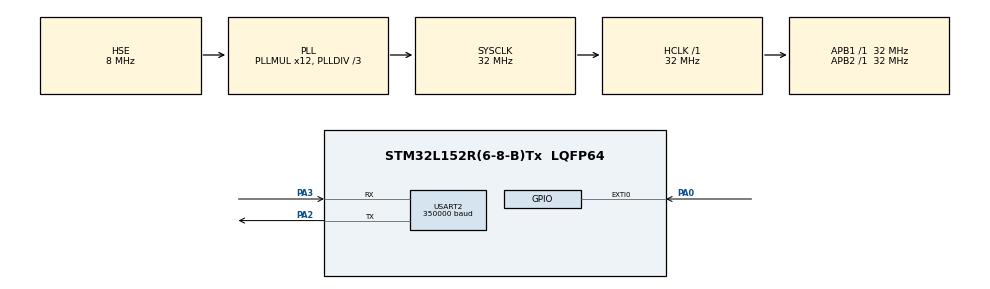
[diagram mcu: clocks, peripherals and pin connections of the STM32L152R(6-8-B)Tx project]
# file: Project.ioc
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ADC.Channel-0\#ChannelRegularConversion=ADC_CHANNEL_VREFINT
ADC.Channel-2\#ChannelRegularConversion=ADC_CHANNEL_TEMPSENSOR
ADC.ContinuousConvMode=ENABLE
ADC.DMAContinuousRequests=ENABLE
ADC.DataAlign=ADC_DATAALIGN_RIGHT
ADC.EOCSelection=ADC_EOC_SINGLE_CONV
ADC.EnableAnalogWatchDog=false
ADC.NbrOfConversion=2
ADC.NbrOfConversionFlag=1
ADC.Rank-0\#ChannelRegularConversion=1
ADC.Rank-2\#ChannelRegularConversion=2
ADC.Resolution=ADC_RESOLUTION_12B
ADC.SamplingTime-0\#ChannelRegularConversion=ADC_SAMPLETIME_192CYCLES
ADC.SamplingTime-2\#ChannelRegularConversion=ADC_SAMPLETIME_192CYCLES
ADC.ScanConvMode=ADC_SCAN_ENABLE
Dma.ADC.0.Direction=DMA_PERIPH_TO_MEMORY
Dma.ADC.0.Instance=DMA1_Channel1
Dma.ADC.0.MemDataAlignment=DMA_MDATAALIGN_WORD
Dma.ADC.0.MemInc=DMA_MINC_ENABLE
Dma.ADC.0.Mode=DMA_CIRCULAR
Dma.ADC.0.PeriphDataAlignment=DMA_PDATAALIGN_WORD
Dma.ADC.0.PeriphInc=DMA_PINC_DISABLE
Dma.ADC.0.Priority=DMA_PRIORITY_HIGH
Dma.Request0=ADC
Mcu.Family=STM32L1
Mcu.Name=STM32L152R(6-8-B)Tx
Mcu.Package=LQFP64
NVIC.ADC1_IRQn=true\:0\:0\:false\:false\:true\:true\:true
NVIC.DMA1_Channel1_IRQn=true\:0\:0\:false\:false\:true\:false\:true
NVIC.EXTI0_IRQn=true\:0\:0\:false\:false\:true\:true\:true
NVIC.PriorityGroup=NVIC_PRIORITYGROUP_4
PA0-WKUP1.Signal=GPXTI0
PA2.Mode=Asynchronous
PA2.Signal=USART2_TX
PA3.Mode=Asynchronous
PA3.Signal=USART2_RX
PC14-OSC32_IN.Mode=LSE-External-Oscillator
PC14-OSC32_IN.Signal=RCC_OSC32_IN
PC15-OSC32_OUT.Mode=LSE-External-Oscillator
PC15-OSC32_OUT.Signal=RCC_OSC32_OUT
PH0-OSC_IN.Mode=HSE-External-Oscillator
PH0-OSC_IN.Signal=RCC_OSC_IN
PH1-OSC_OUT.Mode=HSE-External-Oscillator
PH1-OSC_OUT.Signal=RCC_OSC_OUT
ProjectManager.HeapSize=0x200
ProjectManager.StackSize=0x400
ProjectManager.TargetToolchain=STM32CubeIDE
RCC.48MHZClocksFreq_Value=48000000
RCC.AHBFreq_Value=32000000
RCC.APB1Freq_Value=32000000
RCC.APB1TimFreq_Value=32000000
RCC.APB2Freq_Value=32000000
RCC.APB2TimFreq_Value=32000000
RCC.HCLKFreq_Value=32000000
RCC.HSE_VALUE=8000000
RCC.HSI_VALUE=16000000
RCC.MSI_VALUE=2097000
RCC.PLLDIV=RCC_PLL_DIV3
RCC.PLLMUL=RCC_PLL_MUL12
RCC.PLLSourceVirtual=RCC_PLLSOURCE_HSE
RCC.RTCClockSelectionVirtual=RCC_RTCCLKSOURCE_LSE
RCC.SYSCLKFreq_VALUE=32000000
RCC.SYSCLKSource=RCC_SYSCLKSOURCE_PLLCLK
RCC.USBOutput=48000000
RCC.VCOOutputFreq_Value=96000000
USART2.BaudRate=350000
USART2.VirtualMode=VM_ASYNC
VP_ADC_TempSens_Input.Mode=IN-TempSens
VP_ADC_Vref_Input.Mode=IN-Vrefint
board=STM32L-DISCOVERY

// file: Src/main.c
/* USER CODE BEGIN Header */
/**
  ******************************************************************************
  * @file           : main.c
  * @brief          : Main program body
  ******************************************************************************
  * @attention
  *
  * <h2><center>&copy; Copyright (c) 2019 STMicroelectronics.
  * All rights reserved.</center></h2>
  *
  * This software component is licensed by ST under BSD 3-Clause license,
  * the "License"; You may not use this file except in compliance with the
  * License. You may obtain a copy of the License at:
  *                        opensource.org/licenses/BSD-3-Clause
  *
  ******************************************************************************
  */
/* USER CODE END Header */

#include "main.h"

/* USER CODE BEGIN PD */
#define CHUNK_SIZE 512
#define CHUNK_NUM (16384 / CHUNK_SIZE)

uint8_t send_en = 1;

/* USER CODE END PD */

ADC_HandleTypeDef hadc;
DMA_HandleTypeDef hdma_adc;

UART_HandleTypeDef huart2;

void SystemClock_Config(void);
static void MX_GPIO_Init(void);
static void MX_DMA_Init(void);
static void MX_ADC_Init(void);
static void MX_USART2_UART_Init(void);
/* USER CODE BEGIN PFP */
void User_Init(void);

/* USER CODE END PFP */

/* USER CODE BEGIN 0 */
#ifdef __GNUC__
#define PUTCHAR_PROTOTYPE int __io_putchar(int ch)
#define GETCHAR_PROTOTYPE int __io_getchar(void)
#else
#define PUTCHAR_PROTOTYPE int fputc(int ch, FILE *f)
#define GETCHAR_PROTOTYPE int fgetc(FILE *f)
#endif

/* USER CODE BEGIN 0 */
PUTCHAR_PROTOTYPE
{
	HAL_UART_Transmit(&huart2, (uint8_t *)&ch, 1, 0xFFFF);
	return ch;
}

GETCHAR_PROTOTYPE
{
	char ch;
	HAL_UART_Receive(&huart2, (uint8_t *)&ch, 1, 0xFFFF);

	return ch;
}
/* USER CODE END 0 */

int main(void)
{
  /* USER CODE BEGIN 1 */

  // Vector to store the values of the ADC
  // The first value is the vrefint readout
  // The second is the temperature readout
  uint32_t adc_values[2];
  /* USER CODE END 1 */

  /* MCU Configuration--------------------------------------------------------*/

  /* Reset of all peripherals, Initializes the Flash interface and the Systick. */
  HAL_Init();

  /* Configure the system clock */
  SystemClock_Config();

  /* Initialize all configured peripherals */
  MX_GPIO_Init();
  MX_DMA_Init();
  MX_ADC_Init();
  MX_USART2_UART_Init();
  /* USER CODE BEGIN 2 */
  __HAL_ADC_ENABLE(&hadc);
  HAL_ADC_Start_DMA(&hadc, adc_values, 2);
  /* USER CODE END 2 */

  /* Infinite loop */
  /* USER CODE BEGIN WHILE */
  while (1)
  {
      uint8_t *base_p = (uint8_t *)0x20000000;
      uint8_t *uid_p = (uint8_t *)0x1FF80050;

      uint16_t *vdd_cal = (uint16_t *)0x1FF80078;

      uint16_t *temp30_cal = (uint16_t *)0x1FF8007A;
      uint16_t *temp110_cal = (uint16_t *)0x1FF8007E;

      if(send_en) {
	  // Waffer number
	  printf("%#02x", (uint8_t)*uid_p); uid_p++;

	  // Lot number
	  for(int i = 0; i < 7; ++i)
	      printf("%01X",(uint8_t)*(uid_p + i));

	 // Offset the memory
	 uid_p = (uint32_t *)0x1FF80064;

	 for(int i = 0; i < 4; ++i) {
	     printf("%01X", (uint8_t)*(uid_p + i)); // X/Y Coords in BCD
	 }
	 printf("\n");

	 // Calibration data for later computations
	 printf("%d\n", *temp30_cal);
	 printf("%d\n", *temp110_cal);
	 printf("%d\n", *vdd_cal);

      	 for(int e = 0; e < CHUNK_NUM; ++e) {
      	     // Memory address of the chunk
      	     printf("%p\n", (void *)base_p);

      	     // Voltage value
      	     printf("%d\n", adc_values[0]);

      	     // Temperature value
      	     printf("%d\n", adc_values[1]);

      	     // Memory dump of the corresponding region
      	     for(int c = 0; c < CHUNK_SIZE; ++c)
      		 printf("%u ", *(base_p + c));
      	     printf("\n");

      	     base_p += CHUNK_SIZE;
      	  }
      	  send_en = 0;
      	}
      while(1) {};
    /* USER CODE END WHILE */

  }
}

void SystemClock_Config(void)
{
  RCC_OscInitTypeDef RCC_OscInitStruct = {0};
  RCC_ClkInitTypeDef RCC_ClkInitStruct = {0};

  /** Configure the main internal regulator output voltage
  */
  __HAL_PWR_VOLTAGESCALING_CONFIG(PWR_REGULATOR_VOLTAGE_SCALE1);
  /** Initializes the CPU, AHB and APB busses clocks
  */
  RCC_OscInitStruct.OscillatorType = RCC_OSCILLATORTYPE_HSI|RCC_OSCILLATORTYPE_HSE;
  RCC_OscInitStruct.HSEState = RCC_HSE_ON;
  RCC_OscInitStruct.HSIState = RCC_HSI_ON;
  RCC_OscInitStruct.HSICalibrationValue = RCC_HSICALIBRATION_DEFAULT;
  RCC_OscInitStruct.PLL.PLLState = RCC_PLL_ON;
  RCC_OscInitStruct.PLL.PLLSource = RCC_PLLSOURCE_HSE;
  RCC_OscInitStruct.PLL.PLLMUL = RCC_PLL_MUL12;
  RCC_OscInitStruct.PLL.PLLDIV = RCC_PLL_DIV3;
  if (HAL_RCC_OscConfig(&RCC_OscInitStruct) != HAL_OK)
  {
    Error_Handler();
  }
  /** Initializes the CPU, AHB and APB busses clocks
  */
  RCC_ClkInitStruct.ClockType = RCC_CLOCKTYPE_HCLK|RCC_CLOCKTYPE_SYSCLK
                              |RCC_CLOCKTYPE_PCLK1|RCC_CLOCKTYPE_PCLK2;
  RCC_ClkInitStruct.SYSCLKSource = RCC_SYSCLKSOURCE_PLLCLK;
  RCC_ClkInitStruct.AHBCLKDivider = RCC_SYSCLK_DIV1;
  RCC_ClkInitStruct.APB1CLKDivider = RCC_HCLK_DIV1;
  RCC_ClkInitStruct.APB2CLKDivider = RCC_HCLK_DIV1;

  if (HAL_RCC_ClockConfig(&RCC_ClkInitStruct, FLASH_LATENCY_1) != HAL_OK)
  {
    Error_Handler();
  }
}

static void MX_ADC_Init(void)
{

  ADC_ChannelConfTypeDef sConfig = {0};

  /** Configure the global features of the ADC (Clock, Resolution, Data Alignment and number of conversion)
  */
  hadc.Instance = ADC1;
  hadc.Init.ClockPrescaler = ADC_CLOCK_ASYNC_DIV1;
  hadc.Init.Resolution = ADC_RESOLUTION_12B;
  hadc.Init.DataAlign = ADC_DATAALIGN_RIGHT;
  hadc.Init.ScanConvMode = ADC_SCAN_ENABLE;
  hadc.Init.EOCSelection = ADC_EOC_SINGLE_CONV;
  hadc.Init.LowPowerAutoWait = ADC_AUTOWAIT_DISABLE;
  hadc.Init.LowPowerAutoPowerOff = ADC_AUTOPOWEROFF_DISABLE;
  hadc.Init.ChannelsBank = ADC_CHANNELS_BANK_A;
  hadc.Init.ContinuousConvMode = ENABLE;
  hadc.Init.NbrOfConversion = 2;
  hadc.Init.DiscontinuousConvMode = DISABLE;
  hadc.Init.ExternalTrigConv = ADC_SOFTWARE_START;
  hadc.Init.ExternalTrigConvEdge = ADC_EXTERNALTRIGCONVEDGE_NONE;
  hadc.Init.DMAContinuousRequests = ENABLE;
  if (HAL_ADC_Init(&hadc) != HAL_OK)
  {
    Error_Handler();
  }
  /** Configure for the selected ADC regular channel its corresponding rank in the sequencer and its sample time.
  */
  sConfig.Channel = ADC_CHANNEL_VREFINT;
  sConfig.Rank = ADC_REGULAR_RANK_1;
  sConfig.SamplingTime = ADC_SAMPLETIME_192CYCLES;
  if (HAL_ADC_ConfigChannel(&hadc, &sConfig) != HAL_OK)
  {
    Error_Handler();
  }
  /** Configure for the selected ADC regular channel its corresponding rank in the sequencer and its sample time.
  */
  sConfig.Channel = ADC_CHANNEL_TEMPSENSOR;
  sConfig.Rank = ADC_REGULAR_RANK_2;
  if (HAL_ADC_ConfigChannel(&hadc, &sConfig) != HAL_OK)
  {
    Error_Handler();
  }

}

static void MX_USART2_UART_Init(void)
{

  huart2.Instance = USART2;
  huart2.Init.BaudRate = 350000;
  huart2.Init.WordLength = UART_WORDLENGTH_8B;
  huart2.Init.StopBits = UART_STOPBITS_1;
  huart2.Init.Parity = UART_PARITY_NONE;
  huart2.Init.Mode = UART_MODE_TX_RX;
  huart2.Init.HwFlowCtl = UART_HWCONTROL_NONE;
  huart2.Init.OverSampling = UART_OVERSAMPLING_16;
  if (HAL_UART_Init(&huart2) != HAL_OK)
  {
    Error_Handler();
  }

}

static void MX_DMA_Init(void)
{

  /* DMA controller clock enable */
  __HAL_RCC_DMA1_CLK_ENABLE();

  /* DMA interrupt init */
  /* DMA1_Channel1_IRQn interrupt configuration */
  HAL_NVIC_SetPriority(DMA1_Channel1_IRQn, 0, 0);
  HAL_NVIC_EnableIRQ(DMA1_Channel1_IRQn);

}

static void MX_GPIO_Init(void)
{
  GPIO_InitTypeDef GPIO_InitStruct = {0};

  /* GPIO Ports Clock Enable */
  __HAL_RCC_GPIOC_CLK_ENABLE();
  __HAL_RCC_GPIOH_CLK_ENABLE();
  __HAL_RCC_GPIOA_CLK_ENABLE();
  __HAL_RCC_GPIOB_CLK_ENABLE();
  __HAL_RCC_GPIOD_CLK_ENABLE();

  /*Configure GPIO pins : PC13 PC0 PC1 PC2
                           PC3 PC4 PC5 PC6
                           PC7 PC8 PC9 PC10
                           PC11 PC12 */
  GPIO_InitStruct.Pin = GPIO_PIN_13|GPIO_PIN_0|GPIO_PIN_1|GPIO_PIN_2
                          |GPIO_PIN_3|GPIO_PIN_4|GPIO_PIN_5|GPIO_PIN_6
                          |GPIO_PIN_7|GPIO_PIN_8|GPIO_PIN_9|GPIO_PIN_10
                          |GPIO_PIN_11|GPIO_PIN_12;
  GPIO_InitStruct.Mode = GPIO_MODE_ANALOG;
  GPIO_InitStruct.Pull = GPIO_NOPULL;
  HAL_GPIO_Init(GPIOC, &GPIO_InitStruct);

  /*Configure GPIO pin : PA0 */
  GPIO_InitStruct.Pin = GPIO_PIN_0;
  GPIO_InitStruct.Mode = GPIO_MODE_IT_RISING;
  GPIO_InitStruct.Pull = GPIO_NOPULL;
  HAL_GPIO_Init(GPIOA, &GPIO_InitStruct);

  /*Configure GPIO pins : PA1 PA4 PA5 PA6
                           PA7 PA8 PA9 PA10
                           PA11 PA12 PA13 PA14
                           PA15 */
  GPIO_InitStruct.Pin = GPIO_PIN_1|GPIO_PIN_4|GPIO_PIN_5|GPIO_PIN_6
                          |GPIO_PIN_7|GPIO_PIN_8|GPIO_PIN_9|GPIO_PIN_10
                          |GPIO_PIN_11|GPIO_PIN_12|GPIO_PIN_13|GPIO_PIN_14
                          |GPIO_PIN_15;
  GPIO_InitStruct.Mode = GPIO_MODE_ANALOG;
  GPIO_InitStruct.Pull = GPIO_NOPULL;
  HAL_GPIO_Init(GPIOA, &GPIO_InitStruct);

  /*Configure GPIO pins : PB0 PB1 PB2 PB10
                           PB11 PB12 PB13 PB14
                           PB15 PB3 PB4 PB5
                           PB6 PB7 PB8 PB9 */
  GPIO_InitStruct.Pin = GPIO_PIN_0|GPIO_PIN_1|GPIO_PIN_2|GPIO_PIN_10
                          |GPIO_PIN_11|GPIO_PIN_12|GPIO_PIN_13|GPIO_PIN_14
                          |GPIO_PIN_15|GPIO_PIN_3|GPIO_PIN_4|GPIO_PIN_5
                          |GPIO_PIN_6|GPIO_PIN_7|GPIO_PIN_8|GPIO_PIN_9;
  GPIO_InitStruct.Mode = GPIO_MODE_ANALOG;
  GPIO_InitStruct.Pull = GPIO_NOPULL;
  HAL_GPIO_Init(GPIOB, &GPIO_InitStruct);

  /*Configure GPIO pin : PD2 */
  GPIO_InitStruct.Pin = GPIO_PIN_2;
  GPIO_InitStruct.Mode = GPIO_MODE_ANALOG;
  GPIO_InitStruct.Pull = GPIO_NOPULL;
  HAL_GPIO_Init(GPIOD, &GPIO_InitStruct);

  /* EXTI interrupt init*/
  HAL_NVIC_SetPriority(EXTI0_IRQn, 0, 0);
  HAL_NVIC_EnableIRQ(EXTI0_IRQn);

}

/* USER CODE BEGIN 4 */
void HAL_GPIO_EXTI_Callback(uint16_t GPIO_Pin)
{
	send_en = 1;
}
/* USER CODE END 4 */

void Error_Handler(void)
{
}

/************************ (C) COPYRIGHT STMicroelectronics *****END OF FILE****/
